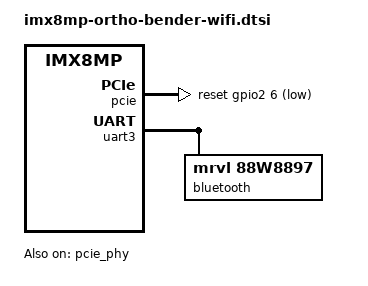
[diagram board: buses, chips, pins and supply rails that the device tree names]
// SPDX-License-Identifier: (GPL-2.0+ OR MIT)
/*
 * WiFi / Bluetooth subsystem - Marvell 88W8997 (M.2 Key E, J10)
 *
 * Purpose : Activate the PCIe WiFi and UART Bluetooth interfaces on the
 *           i.MX8MP EVK.  The Marvell 88W8997 module is the NXP EVK
 *           default combo chip fitted in the M.2 Key E slot (J10).
 *
 * WiFi  : PCIe — pcie0 (mwifiex_pcie driver)
 * BT    : UART — uart3 (mrvl vendor HCI transport)
 *
 * The EVK imx8mp-evk.dts already contains the pcie0 and uart nodes.
 * This overlay ensures they are enabled with the correct parameters
 * for the ortho-bender application.
 *
 * Author   : Ortho-Bender BSP team
 * SW Class : IEC 62304 Class B
 */

/*
 * PCIe0 — WiFi host controller (Marvell 88W8997)
 *
 * The 88W8997 uses a single-lane PCIe Gen 2 link.  The EVK routes
 * PCIe0 to the M.2 Key E connector (J10).
 *
 * W_DISABLE# (WiFi RF kill) is active-low; when asserted the 88W8997
 * powers down its radio.  The EVK ties this to a GPIO or leaves it
 * active (de-asserted) by default.
 *
 * The mwifiex_pcie driver auto-probes on PCI vendor/device ID match.
 * No explicit DT child node is needed for enumeration.
 */
&pcie {
	pinctrl-names = "default";
	pinctrl-0 = <&pinctrl_pcie0>;
	reset-gpio = <&gpio2 6 GPIO_ACTIVE_LOW>;
	clocks = <&clk IMX8MP_CLK_HSIO_ROOT>,
		 <&clk IMX8MP_CLK_PCIE_AUX>,
		 <&clk IMX8MP_CLK_HSIO_AXI>,
		 <&clk IMX8MP_CLK_PCIE_ROOT>;
	clock-names = "pcie", "pcie_aux", "pcie_phy", "pcie_bus";
	assigned-clocks = <&clk IMX8MP_CLK_HSIO_AXI>,
			  <&clk IMX8MP_CLK_PCIE_AUX>;
	assigned-clock-rates = <500000000>, <10000000>;
	assigned-clock-parents = <&clk IMX8MP_SYS_PLL2_500M>,
				 <&clk IMX8MP_SYS_PLL2_50M>;
	status = "okay";
};

&pcie_phy {
	fsl,refclk-pad-mode = <IMX8_PCIE_REFCLK_PAD_INPUT>;
	fsl,clkreq-unsupported;
	clocks = <&hsio_blk_ctrl>;
	clock-names = "ref";
	status = "okay";
};

/*
 * uart3 — Bluetooth HCI UART (Marvell 88W8997 BT subsystem)
 *
 * The 88W8997 BT uses UART with H:4 HCI transport and Marvell vendor
 * extensions for firmware download.  Hardware flow control (RTS/CTS)
 * is required.
 *
 * The EVK routes UART3 TXD/RXD/CTS/RTS to the M.2 Key E BT pads.
 */
&uart3 {
	pinctrl-names = "default";
	pinctrl-0 = <&pinctrl_uart3>;
	assigned-clocks = <&clk IMX8MP_CLK_UART3>;
	assigned-clock-parents = <&clk IMX8MP_SYS_PLL1_80M>;
	uart-has-rtscts;
	status = "okay";

	bluetooth {
		compatible = "mrvl,88w8897";
		/*
		 * max-speed matches the firmware download baud rate.
		 * After FW download the host negotiates a higher baud.
		 */
		max-speed = <3000000>;
	};
};
